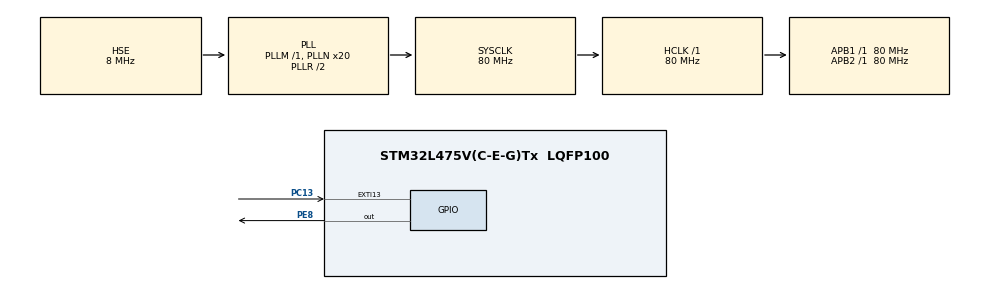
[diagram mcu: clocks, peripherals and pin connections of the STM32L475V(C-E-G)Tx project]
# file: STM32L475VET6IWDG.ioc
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IWDG.Prescaler=IWDG_PRESCALER_32
IWDG.Reload=1000-1
IWDG.Window=4096-1
Mcu.Family=STM32L4
Mcu.Name=STM32L475V(C-E-G)Tx
Mcu.Package=LQFP100
NVIC.EXTI15_10_IRQn=true\:0\:0\:false\:false\:true\:true\:true\:true
NVIC.PriorityGroup=NVIC_PRIORITYGROUP_2
PC13.GPIO_ModeDefaultEXTI=GPIO_MODE_IT_RISING
PC13.GPIO_PuPd=GPIO_PULLDOWN
PC13.Signal=GPXTI13
PE8.GPIO_ModeDefaultOutputPP=GPIO_MODE_OUTPUT_PP
PE8.GPIO_PuPd=GPIO_PULLUP
PE8.GPIO_Speed=GPIO_SPEED_FREQ_HIGH
PE8.PinState=GPIO_PIN_SET
PE8.Signal=GPIO_Output
PH0-OSC_IN\ (PH0).Mode=HSE-External-Oscillator
PH0-OSC_IN\ (PH0).Signal=RCC_OSC_IN
PH1-OSC_OUT\ (PH1).Mode=HSE-External-Oscillator
PH1-OSC_OUT\ (PH1).Signal=RCC_OSC_OUT
ProjectManager.HeapSize=0x200
ProjectManager.StackSize=0x400
ProjectManager.TargetToolchain=MDK-ARM V5.32
RCC.ADCFreq_Value=32000000
RCC.AHBFreq_Value=80000000
RCC.APB1Freq_Value=80000000
RCC.APB1TimFreq_Value=80000000
RCC.APB2Freq_Value=80000000
RCC.APB2TimFreq_Value=80000000
RCC.CortexFreq_Value=80000000
RCC.HCLKFreq_Value=80000000
RCC.HSE_VALUE=8000000
RCC.HSI_VALUE=16000000
RCC.LSE_VALUE=32768
RCC.MSI_VALUE=4000000
RCC.PLLN=20
RCC.PLLSourceVirtual=RCC_PLLSOURCE_HSE
RCC.SYSCLKFreq_VALUE=80000000
RCC.SYSCLKSource=RCC_SYSCLKSOURCE_PLLCLK
RCC.USBFreq_Value=32000000
RCC.VCOOutputFreq_Value=160000000
VP_IWDG_VS_IWDG.Mode=IWDG_Activate
board=custom

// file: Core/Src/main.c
/* USER CODE BEGIN Header */
/**
  ******************************************************************************
  * @file           : main.c
  * @brief          : Main program body
  ******************************************************************************
  * @attention
  *
  * Copyright (c) 2023 STMicroelectronics.
  * All rights reserved.
  *
  * This software is licensed under terms that can be found in the LICENSE file
  * in the root directory of this software component.
  * If no LICENSE file comes with this software, it is provided AS-IS.
  *
  ******************************************************************************
  */
/* USER CODE END Header */
#include "main.h"
#include "iwdg.h"
#include "gpio.h"

/* USER CODE BEGIN Includes */
#include "delay.h"

/* USER CODE END Includes */

void SystemClock_Config(void);

int main(void)
{

  /* MCU Configuration--------------------------------------------------------*/

  /* Reset of all peripherals, Initializes the Flash interface and the Systick. */
  HAL_Init();

  /* Configure the system clock */
  SystemClock_Config();

  /* USER CODE BEGIN SysInit */
	delay_init(80);

  /* USER CODE END SysInit */

  /* Initialize all configured peripherals */
  MX_GPIO_Init();

  /* USER CODE BEGIN 2 */
	delay_ms(1000);
	MX_IWDG_Init();
	HAL_GPIO_WritePin(GPIOE, GPIO_PIN_8, GPIO_PIN_RESET);
  /* USER CODE END 2 */

  /* Infinite loop */
  /* USER CODE BEGIN WHILE */
  while (1)
  {
	  delay_ms(10);
    /* USER CODE END WHILE */

  }
}

void SystemClock_Config(void)
{
  RCC_OscInitTypeDef RCC_OscInitStruct = {0};
  RCC_ClkInitTypeDef RCC_ClkInitStruct = {0};

  /** Configure the main internal regulator output voltage
  */
  if (HAL_PWREx_ControlVoltageScaling(PWR_REGULATOR_VOLTAGE_SCALE1) != HAL_OK)
  {
    Error_Handler();
  }

  /** Initializes the RCC Oscillators according to the specified parameters
  * in the RCC_OscInitTypeDef structure.
  */
  RCC_OscInitStruct.OscillatorType = RCC_OSCILLATORTYPE_LSI|RCC_OSCILLATORTYPE_HSE;
  RCC_OscInitStruct.HSEState = RCC_HSE_ON;
  RCC_OscInitStruct.LSIState = RCC_LSI_ON;
  RCC_OscInitStruct.PLL.PLLState = RCC_PLL_ON;
  RCC_OscInitStruct.PLL.PLLSource = RCC_PLLSOURCE_HSE;
  RCC_OscInitStruct.PLL.PLLM = 1;
  RCC_OscInitStruct.PLL.PLLN = 20;
  RCC_OscInitStruct.PLL.PLLP = RCC_PLLP_DIV7;
  RCC_OscInitStruct.PLL.PLLQ = RCC_PLLQ_DIV2;
  RCC_OscInitStruct.PLL.PLLR = RCC_PLLR_DIV2;
  if (HAL_RCC_OscConfig(&RCC_OscInitStruct) != HAL_OK)
  {
    Error_Handler();
  }

  /** Initializes the CPU, AHB and APB buses clocks
  */
  RCC_ClkInitStruct.ClockType = RCC_CLOCKTYPE_HCLK|RCC_CLOCKTYPE_SYSCLK
                              |RCC_CLOCKTYPE_PCLK1|RCC_CLOCKTYPE_PCLK2;
  RCC_ClkInitStruct.SYSCLKSource = RCC_SYSCLKSOURCE_PLLCLK;
  RCC_ClkInitStruct.AHBCLKDivider = RCC_SYSCLK_DIV1;
  RCC_ClkInitStruct.APB1CLKDivider = RCC_HCLK_DIV1;
  RCC_ClkInitStruct.APB2CLKDivider = RCC_HCLK_DIV1;

  if (HAL_RCC_ClockConfig(&RCC_ClkInitStruct, FLASH_LATENCY_4) != HAL_OK)
  {
    Error_Handler();
  }
}

void Error_Handler(void)
{
  __disable_irq();
  while (1)
  {
  }
}
